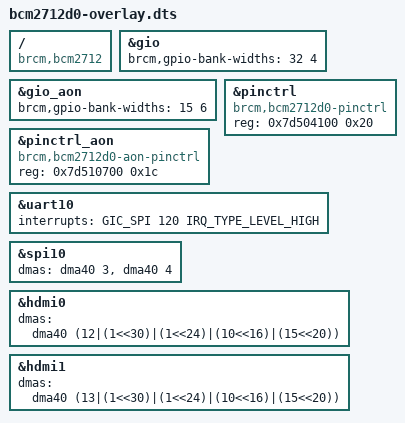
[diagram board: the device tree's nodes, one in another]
// SPDX-License-Identifier: GPL-2.0
/dts-v1/;
/plugin/;

#include <dt-bindings/interrupt-controller/irq.h>
#include <dt-bindings/interrupt-controller/arm-gic.h>

/ {
	compatible = "brcm,bcm2712";

	fragment@0 {
		target = <&gio>;
		__overlay__ {
			brcm,gpio-bank-widths = <32 4>;
		};
	};

	fragment@1 {
		target = <&gio_aon>;
		__overlay__ {
			brcm,gpio-bank-widths = <15 6>;
		};
	};

	fragment@2 {
		target = <&pinctrl>;
		__overlay__ {
			compatible = "brcm,bcm2712d0-pinctrl";
			reg = <0x7d504100 0x20>;
		};
	};

	fragment@3 {
		target = <&pinctrl_aon>;
		__overlay__ {
			compatible = "brcm,bcm2712d0-aon-pinctrl";
			reg = <0x7d510700 0x1c>;
		};
	};

	fragment@4 {
		target = <&uart10>;
		__overlay__ {
			interrupts = <GIC_SPI 120 IRQ_TYPE_LEVEL_HIGH>;
		};
	};

	fragment@5 {
		target = <&spi10>;
		__overlay__ {
			dmas = <&dma40 3>, <&dma40 4>;
		};
	};

	fragment@6 {
		target = <&hdmi0>;
		__overlay__ {
			dmas = <&dma40 (12|(1<<30)|(1<<24)|(10<<16)|(15<<20))>;
		};
	};

	fragment@7 {
		target = <&hdmi1>;
		__overlay__ {
			dmas = <&dma40 (13|(1<<30)|(1<<24)|(10<<16)|(15<<20))>;
		};
	};
};
